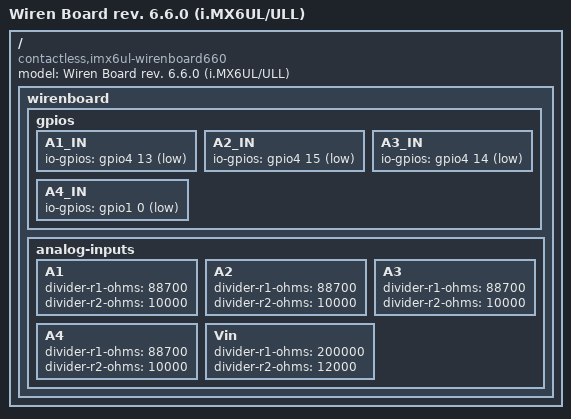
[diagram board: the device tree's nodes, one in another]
/dts-v1/;

#include "imx6ul-wirenboard6x-common.dtsi"

/ {
	model = "Wiren Board rev. 6.6.0 (i.MX6UL/ULL)";
	compatible = "contactless,imx6ul-wirenboard660", "contactless,imx6ul-wirenboard65", "contactless,imx6ul-wirenboard61", "contactless,imx6ul-wirenboard60", "contactless,imx6ul-wirenboard-evk", "fsl,imx6ul-14x14-evk", "fsl,imx6ul";
	wirenboard {

		gpios {
			A1_IN {
				io-gpios = <&gpio4 13 1>; /* inverted */
			};

			A2_IN {
				io-gpios = <&gpio4 15 1>; /* inverted */
			};

			A3_IN {
				io-gpios = <&gpio4 14 1>; /* inverted */
			};

			A4_IN {
				io-gpios = <&gpio1 0 1>; /* inverted */
			};
		};

		analog-inputs {
			A1 {
				divider-r1-ohms = <88700>;
				divider-r2-ohms = <10000>;
			};

			A2 {
				divider-r1-ohms = <88700>;
				divider-r2-ohms = <10000>;
			};

			A3 {
				divider-r1-ohms = <88700>;
				divider-r2-ohms = <10000>;
			};

			A4 {
				divider-r1-ohms = <88700>;
				divider-r2-ohms = <10000>;
			};
			Vin {
				divider-r1-ohms = <200000>;
				divider-r2-ohms = <12000>;
			};
		};
    };
};
